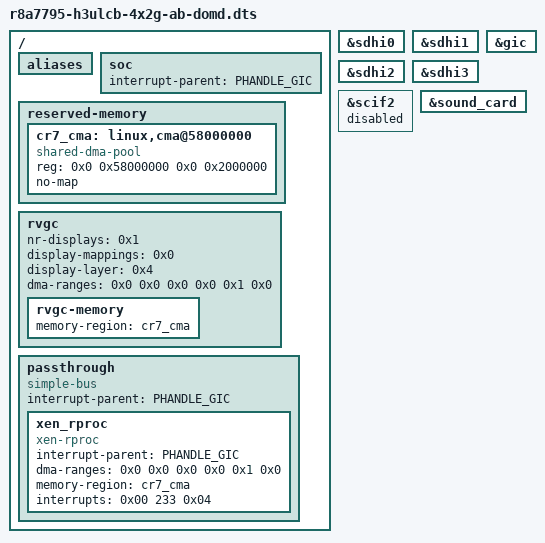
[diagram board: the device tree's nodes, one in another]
// SPDX-License-Identifier: GPL-2.0
/*
 * Device Tree Source for the H3ULCB Aos box (CCPF Starter kit) board
 * running XEN hypervisor
 *
 * Copyright (C) 2021 Renesas Electronics Corp.
 * Copyright (C) 2021 EPAM Systems, Inc.
 */

#include "r8a77951-ulcb.dts"
#include "ulcb-ab.dtsi"


/*
 * The device tree compiler (DTC) is allocating the phandle from 1 to
 * onwards. Reserve a high value for the GIC phandle.
 */
#define PHANDLE_GIC (65000)

/ {
	aliases {
		/delete-property/ i2c4;
	};

	soc {
		/* This must point to Xen interrupt-parent */
		interrupt-parent = <PHANDLE_GIC>;
	};

	reserved-memory {
		#address-cells = <0x2>;
		#size-cells = <0x2>;
		ranges;
		cr7_cma: linux,cma@58000000 {
			compatible = "shared-dma-pool";
			reg = <0x0 0x58000000 0x0 0x2000000>;
			no-map;
			/delete-property/ reusable;
			/delete-property/ linux,cma-default;
		};
		/delete-node/ linux,lossy_decompress@54000000;
		/delete-node/ linux,adsp@57000000;
		/delete-node/ linux,multimedia@70000000;
	};

	/delete-node/ mmngr;

	rvgc {
		nr-displays = <0x1>;
		display-mappings = <0x0>;
		display-layer = <0x4>;

		dma-ranges = <0x0 0x0 0x0 0x0 0x1 0x0>;
		rvgc-memory {
			memory-region = <&cr7_cma>;
		};
	};

	passthrough {
		#address-cells = <0x2>;
		#size-cells = <0x2>;
		interrupt-parent = <PHANDLE_GIC>;
		compatible = "simple-bus";

		xen_rproc {
			interrupt-parent = <PHANDLE_GIC>;
			dma-ranges = <0x0 0x0 0x0 0x0 0x1 0x0>;
			memory-region = <&cr7_cma>;
			compatible = "xen-rproc";
			interrupts = <0x00 233 0x04>;
			interrupt-names = "xen-rproc";
		};
	};

	/*
	 * When creating DT for the guest domain Xen inserts only dummy CPU nodes.
	 * And the number of these inserted CPU nodes is equal to the number of
	 * vCPUs assigned to this domain. All CPU properties which original DT has,
	 * such as OPP, clock, regulator, etc are not passed to the guest’s DT.
	 *
	 * Example of guest vCPU node:
	 *
	 * cpu@0 {
	 *     device_type = "cpu";
	 *     compatible = "arm,armv8";
	 *     enable-method = "psci";
	 *     reg = <0x0>;
	 * };
	 *
	 * This results in the fact that all features expecting a57_x or a53_x
	 * CPU nodes to be present get broken. This is why we have to explicitly
	 * remove the following.
	 */
	/delete-node/thermal-zones;
	/delete-node/pmu_a57;
	/delete-node/pmu_a53;

	/* CR7 is responislbe for graphics */
	/delete-node/ cvbs-in;
	/delete-node/ hdmi-in;
	/delete-node/ hdmi-out;
	/delete-node/ lvds-decoder;

	/delete-node/ lvds;
	/delete-node/ vga;
	/delete-node/ vga-encoder;
};

&sdhi0 {
	/delete-property/iommus;
};

/delete-node/&adsp;

&sdhi1 {
	/delete-property/iommus;
};

&sdhi2 {
	/delete-property/iommus;
};

&sdhi3 {
	/delete-property/iommus;
};

/* Xen will provide its own GIC, mask ours */
&gic {
	compatible = "";
};

&scif2 {
	status = "disabled";
};

&sound_card {
	/delete-property/ dais;
};
